# NANO100BN_v1 register map
File version: 1.0
Registers are 32-bit, read-write, reset 0x0 unless marked. A register's access mark holds for its fields unless they carry their own. Offsets are from the block's base; [hi:lo] are bit positions; {n}, {i} and the like mark numbered series.

## EBI — EBI Register Map
Base 0x50010000
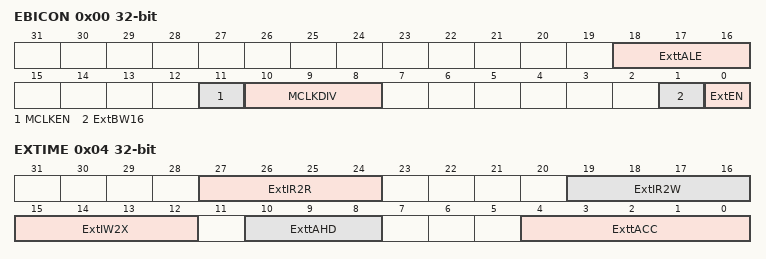
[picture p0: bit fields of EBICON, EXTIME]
0x00 EBICON — External Bus Interface General Control Register
  [18:16] ExttALE — Expand Time of ALE. The ALE width (tALE) to latch the address can be controlled by ExttALE.
  [11] MCLKEN — External Clock Enable. This bit control if EBI generates the clock to external device. If external device is a synchronous device, it's necessary to set this bit high to enable EBI generating clock to external device. If the external device is an asynchronous device, keep this bit low is recommended to save power consumption.
    0=EBI Disabled to generate clock to external device; 1=EBI Enabled to generate clock to external device
  [10:8] MCLKDIV — External Output Clock Divider
  [1] ExtBW16 — EBI Data Width 16-bit. This bit defines if the data bus is 8-bit or 16-bit.
    0=EBI data width is 8-bit; 1=EBI data width is 16-bit
  [0] ExtEN — EBI Enable. This bit is the functional enable bit for EBI.
    0=EBI function is disabled; 1=EBI function is enabled
0x04 EXTIME — External Bus Interface Timing Control Register
  [27:24] ExtIR2R — Idle State Cycle between Read-Read. When read action is finish and next action is going to read, idle state is inserted and nCS return to high if ExtIR2R is not zero.
  [19:16] ExtIR2W — Idle State Cycle between Read-Write. When read action is finish and next action is going to write, idle state is inserted and nCS return to high if ExtIR2W is not zero.
  [15:12] ExtIW2X — Idle State Cycle after Write. When write action is finish, idle state is inserted and nCS return to high if ExtIW2X is not zero.
  [10:8] ExttAHD — EBI Data Access Hold Time. ExttAHD define data access hold time (tAHD).
  [4:0] ExttACC — EBI Data Access Time. ExttACC define data access time (tACC).

## FMC — FMC Register Map
Base 0x5000C000
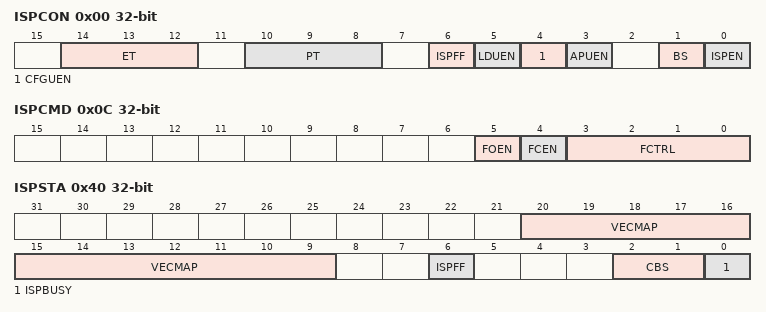
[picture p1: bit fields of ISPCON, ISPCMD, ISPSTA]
0x00 ISPCON — ISP Control Register
  [14:12] ET — Flash Erase Time (Write-protection Bits)
  [10:8] PT — Flash Program Time (Write-protection Bits)
  [6] ISPFF — ISP Fail Flag (Write-protection Bit). This bit is set by hardware when a triggered ISP meets any of the following conditions: (1) APROM writes to itself (2) LDROM writes to itself (3) CONFIG is erased/programmed if CFGUEN is set to 0 (4) Destination address is illegal, such as over an available range. Write 1 to clear.
  [5] LDUEN — LDROM Update Enable (Write-protection Bit). LDROM update enable bit.
    0=LDROM cannot be updated; 1=LDROM can be updated when the chip runs in APROM
  [4] CFGUEN — Enable Config-bits Update by ISP (Write-protection Bit)
    0=Disabling ISP can update config-bits; 1=Enabling ISP can update config-bits
  [3] APUEN — APROM Update Enable (Write-protection Bit). APROM update enable bit.
    0=APROM can not be updated; 1=APROM can be updated when the MCU runs in APROM
  [1] BS — Boot Select (Write-protection Bit). Set/clear this bit to select next booting from LDROM/APROM, respectively. This bit also functions as chip booting status flag, which can be used to check where chip booted from. This bit is initiated with the inversed value of CBS in Config0 after power-on reset; It keeps the same value at other reset.
    0=boot from APROM; 1=boot from LDROM
  [0] ISPEN — ISP Enable (Erite-protection Bit). ISP function enable bit. Set this bit to enable ISP function.
    0=ISP function Disabled; 1=ISP function Enabled
0x04 ISPADR — ISP Address Register
  [31:0] ISPADR — ISP Address. This chip supports word program only. ISPADR[1:0] must be kept 00b for ISP operation, and ISPADR[8:0] must be kept 0_0000_0000b for Vector Page Re-map Command
0x08 ISPDAT — ISP Data Register
  [31:0] ISPDAT — ISP Data. Write data to this register before ISP program operation. Read data from this register after ISP read operation
0x0C ISPCMD — ISP Command Register
  [5] FOEN — ISP Command. The ISP command table is shown as follows.
  [4] FCEN — ISP Command. The ISP command table is shown as follows.
  [3:0] FCTRL — ISP Command. The ISP command table is shown as follows.
0x10 ISPTRG — ISP Trigger Register
  [0] ISPGO — ISP Start Trigger. Write 1 to start ISP operation and this bit will be cleared to 0 by hardware automatically when ISP operation is finished.
    0=ISP operation is finished; 1=ISP is progressing
0x14 DFBADR ro reset 0x1F000 — Data Flash Base Address
  [31:0] DFBA — Data Flash Base Address. This register indicates data flash start address. It is a read only register. The data flash start address is defined by user. Since on chip flash erase unit is 512 bytes, it is mandatory to keep bit 8-0 as 0.
0x40 ISPSTA — ISP Status Register
  [20:9] VECMAP — Vector Page Mapping Address. The current flash address space 0x0000_0000~0x0000_01FF is mapping to address {VEC}AP[11:0], "000000000b"} ~ {VEC}AP[11:0], "111111111b"} Read Only
  [6] ISPFF — ISP Fail Flag. This bit is set by hardware when a triggered ISP meets any of the following conditions: (1) APROM writes to itself. (2) LDROM writes to itself. (3) CONFIG is erased/programmed when the MCU is running in APROM. (4) Destination address is illegal, such as over an available range. Write 1 to clear.
  [2:1] CBS — Config Boot Selection Status
  [0] ISPBUSY — ISP BUSY. Read Only
    0=ISP operation is finished; 1=ISP operation is busy
